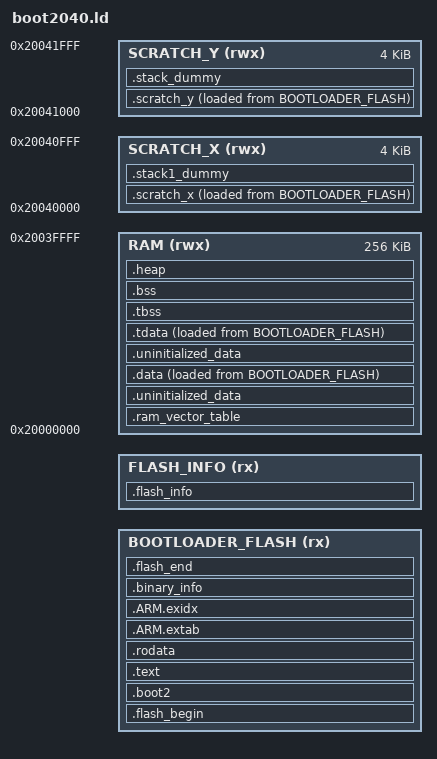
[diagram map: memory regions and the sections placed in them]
/* Based on pico-sdk/src/rp2_common/pico_crt0/rp2040/memmap_default.ld */

INCLUDE linker_definitions.ld

MEMORY
{
    BOOTLOADER_FLASH(rx) : ORIGIN = __FLASH_START, LENGTH = __BOOTLOADER_LENGTH
    FLASH_INFO(rx) : ORIGIN = __FLASH_INFO_START, LENGTH = __FLASH_INFO_LENGTH
    /*
    FLASH_APP(rx) : ORIGIN = __FLASH_APP_START, LENGTH = __FLASH_SLOT_LENGTH
    FLASH_DOWNLOAD_SLOT(rx) : ORIGIN = __FLASH_DOWNLOAD_SLOT_START, LENGTH = __FLASH_SLOT_LENGTH
    */
    RAM(rwx) : ORIGIN =  0x20000000, LENGTH = 256k
    SCRATCH_X(rwx) : ORIGIN = 0x20040000, LENGTH = 4k
    SCRATCH_Y(rwx) : ORIGIN = 0x20041000, LENGTH = 4k
}

ENTRY(_entry_point)

SECTIONS
{
    /* Second stage bootloader is prepended to the image. It must be 256 bytes big
       and checksummed. It is usually built by the boot_stage2 target
       in the Raspberry Pi Pico SDK
    */

    .flash_begin : {
        __flash_binary_start = .;
    } > BOOTLOADER_FLASH

    .boot2 : {
        __boot2_start__ = .;
        KEEP (*(.boot2))
        __boot2_end__ = .;
    } > BOOTLOADER_FLASH

    ASSERT(__boot2_end__ - __boot2_start__ == 256,
        "ERROR: Pico second stage bootloader must be 256 bytes in size")

    /* The second stage will always enter the image at the start of .text.
       The debugger will use the ELF entry point, which is the _entry_point
       symbol if present, otherwise defaults to start of .text.
       This can be used to transfer control back to the bootrom on debugger
       launches only, to perform proper flash setup.
    */

    .text : {
        __logical_binary_start = .;
        KEEP (*(.vectors))
        KEEP (*(.binary_info_header))
        __binary_info_header_end = .;
        KEEP (*(.reset))
        /* TODO revisit this now memset/memcpy/float in ROM */
        /* bit of a hack right now to exclude all floating point and time critical (e.g. memset, memcpy) code from
         * FLASH ... we will include any thing excluded here in .data below by default */
        *(.init)
        *(EXCLUDE_FILE(*libgcc.a: *libc.a:*lib_a-mem*.o *libm.a:) .text*)
        *(.fini)
        /* Pull all c'tors into .text */
        *crtbegin.o(.ctors)
        *crtbegin?.o(.ctors)
        *(EXCLUDE_FILE(*crtend?.o *crtend.o) .ctors)
        *(SORT(.ctors.*))
        *(.ctors)
        /* Followed by destructors */
        *crtbegin.o(.dtors)
        *crtbegin?.o(.dtors)
        *(EXCLUDE_FILE(*crtend?.o *crtend.o) .dtors)
        *(SORT(.dtors.*))
        *(.dtors)

        *(.eh_frame*)
        . = ALIGN(4);
    } > BOOTLOADER_FLASH

    .flash_info : {
        __flash_info_app_vtor = .;
        LONG(__FLASH_APP_START)
        __flash_info_download_slot_vtor = .;
        LONG(__FLASH_DOWNLOAD_SLOT_START)
        __flash_info_is_download_slot_valid = .;
        /* after flashing bootloader, download slot is invalid */
        LONG(0x00000000)
        __flash_info_is_firmware_is_swapped = .;
        /* after flashing bootloader, firmware has not yet been swapped */
        LONG(0x00000000)
        __flash_info_is_after_rollback = .;
        /* after flashing bootloader, app is not affter a rollback */
        LONG(0x00000000)
        __flash_info_should_rollback = .;
        /* after flashing bootloader, rollback shouldn't be performed */
        LONG(0x00000000)
    } > FLASH_INFO

    ASSERT(__flash_info_app_vtor == __FLASH_INFO_APP_HEADER,
            "__FLASH_INFO_APP_HEADER definition in linker_definitions.ld file is not valid")
    ASSERT(__flash_info_download_slot_vtor == __FLASH_INFO_DOWNLOAD_HEADER,
            "__FLASH_INFO_DOWNLOAD_HEADER definition in linker_definitions.ld file is not valid")
    ASSERT(__flash_info_is_download_slot_valid == __FLASH_INFO_IS_DOWNLOAD_SLOT_VALID,
            "__FLASH_INFO_IS_DOWNLOAD_SLOT_VALID definition in linker_definitions.ld file is not valid")
    ASSERT(__flash_info_is_firmware_is_swapped == __FLASH_INFO_IS_FIRMWARE_SWAPPED,
            "__FLASH_INFO_IS_FIRMWARE_SWAPPED definition in linker_definitions.ld file is not valid")
    ASSERT(__flash_info_is_after_rollback == __FLASH_INFO_IS_AFTER_ROLLBACK,
            "__FLASH_INFO_IS_AFTER_ROLLBACK definition in linker_definitions.ld file is not valid")
    ASSERT(__flash_info_should_rollback == __FLASH_INFO_SHOULD_ROLLBACK,
            "__FLASH_INFO_SHOULD_ROLLBACK definition in linker_definitions.ld file is not valid")

    .rodata : {
        *(EXCLUDE_FILE(*libgcc.a: *libc.a:*lib_a-mem*.o *libm.a:) .rodata*)
        . = ALIGN(4);
        *(SORT_BY_ALIGNMENT(SORT_BY_NAME(.flashdata*)))
        . = ALIGN(4);
    } > BOOTLOADER_FLASH

    .ARM.extab :
    {
        *(.ARM.extab* .gnu.linkonce.armextab.*)
    } > BOOTLOADER_FLASH

    __exidx_start = .;
    .ARM.exidx :
    {
        *(.ARM.exidx* .gnu.linkonce.armexidx.*)
    } > BOOTLOADER_FLASH
    __exidx_end = .;

    /* Machine inspectable binary information */
    . = ALIGN(4);
    __binary_info_start = .;
    .binary_info :
    {
        KEEP(*(.binary_info.keep.*))
        *(.binary_info.*)
    } > BOOTLOADER_FLASH
    __binary_info_end = .;
    . = ALIGN(4);

    __etext = .;

    .ram_vector_table (COPY): {
        *(.ram_vector_table)
    } > RAM

    .uninitialized_data (NOLOAD): {
        . = ALIGN(4);
        *(.uninitialized_data*)
    } > RAM

    .data : {
        __data_start__ = .;
        *(vtable)

        *(.time_critical*)

        /* remaining .text and .rodata; i.e. stuff we exclude above because we want it in RAM */
        *(.text*)
        . = ALIGN(4);
        *(.rodata*)
        . = ALIGN(4);

        *(.data*)

        . = ALIGN(4);
        *(.after_data.*)
        . = ALIGN(4);
        /* preinit data */
        PROVIDE_HIDDEN (__mutex_array_start = .);
        KEEP(*(SORT(.mutex_array.*)))
        KEEP(*(.mutex_array))
        PROVIDE_HIDDEN (__mutex_array_end = .);

        . = ALIGN(4);
        /* preinit data */
        PROVIDE_HIDDEN (__preinit_array_start = .);
        KEEP(*(SORT(.preinit_array.*)))
        KEEP(*(.preinit_array))
        PROVIDE_HIDDEN (__preinit_array_end = .);

        . = ALIGN(4);
        /* init data */
        PROVIDE_HIDDEN (__init_array_start = .);
        KEEP(*(SORT(.init_array.*)))
        KEEP(*(.init_array))
        PROVIDE_HIDDEN (__init_array_end = .);

        . = ALIGN(4);
        /* finit data */
        PROVIDE_HIDDEN (__fini_array_start = .);
        *(SORT(.fini_array.*))
        *(.fini_array)
        PROVIDE_HIDDEN (__fini_array_end = .);

        *(.jcr)
        . = ALIGN(4);
        __data_end__ = .;
    } > RAM AT> BOOTLOADER_FLASH

    .uninitialized_data (COPY): {
        . = ALIGN(4);
        *(.uninitialized_data*)
    } > RAM

    .tdata : {
        . = ALIGN(4);
		*(.tdata .tdata.* .gnu.linkonce.td.*)
        /* All data end */
        __tdata_end = .;
    } > RAM AT> BOOTLOADER_FLASH
    PROVIDE(__data_end__ = .);

    .tbss (NOLOAD) : {
        . = ALIGN(4);
        __bss_start__ = .;
        __tls_base = .;
        *(.tbss .tbss.* .gnu.linkonce.tb.*)
        *(.tcommon)

        __tls_end = .;
    } > RAM

    .bss (NOLOAD) : {
        . = ALIGN(4);
        __tbss_end = .;

        *(SORT_BY_ALIGNMENT(SORT_BY_NAME(.bss*)))
        *(COMMON)
        . = ALIGN(4);
        __bss_end__ = .;
    } > RAM

    .heap (NOLOAD):
    {
        __end__ = .;
        end = __end__;
        KEEP(*(.heap*))
    } > RAM
    /* historically on GCC sbrk was growing past __HeapLimit to __StackLimit, however
       to be more compatible, we now set __HeapLimit explicitly to where the end of the heap is */
    __HeapLimit = ORIGIN(RAM) + LENGTH(RAM);

    /* Start and end symbols must be word-aligned */
    .scratch_x : {
        __scratch_x_start__ = .;
        *(.scratch_x.*)
        . = ALIGN(4);
        __scratch_x_end__ = .;
    } > SCRATCH_X AT > BOOTLOADER_FLASH
    __scratch_x_source__ = LOADADDR(.scratch_x);

    .scratch_y : {
        __scratch_y_start__ = .;
        *(.scratch_y.*)
        . = ALIGN(4);
        __scratch_y_end__ = .;
    } > SCRATCH_Y AT > BOOTLOADER_FLASH
    __scratch_y_source__ = LOADADDR(.scratch_y);

    /* .stack*_dummy section doesn't contains any symbols. It is only
     * used for linker to calculate size of stack sections, and assign
     * values to stack symbols later
     *
     * stack1 section may be empty/missing if platform_launch_core1 is not used */

    /* by default we put core 0 stack at the end of scratch Y, so that if core 1
     * stack is not used then all of SCRATCH_X is free.
     */
    .stack1_dummy (NOLOAD):
    {
        *(.stack1*)
    } > SCRATCH_X
    .stack_dummy (NOLOAD):
    {
        KEEP(*(.stack*))
    } > SCRATCH_Y

    .flash_end : {
        PROVIDE(__flash_binary_end = .);
    } > BOOTLOADER_FLASH

    /* stack limit is poorly named, but historically is maximum heap ptr */
    __StackLimit = ORIGIN(RAM) + LENGTH(RAM);
    __StackOneTop = ORIGIN(SCRATCH_X) + LENGTH(SCRATCH_X);
    __StackTop = ORIGIN(SCRATCH_Y) + LENGTH(SCRATCH_Y);
    __StackOneBottom = __StackOneTop - SIZEOF(.stack1_dummy);
    __StackBottom = __StackTop - SIZEOF(.stack_dummy);
    PROVIDE(__stack = __StackTop);

    /* picolibc and LLVM */
    PROVIDE (__heap_start = __end__);
    PROVIDE (__heap_end = __HeapLimit);
    PROVIDE( __tls_align = MAX(ALIGNOF(.tdata), ALIGNOF(.tbss)) );
    PROVIDE( __tls_size_align = (__tls_size + __tls_align - 1) & ~(__tls_align - 1));
    PROVIDE( __arm32_tls_tcb_offset = MAX(8, __tls_align) );

    /* llvm-libc */
    PROVIDE (_end = __end__);
    PROVIDE (__llvm_libc_heap_limit = __HeapLimit);

    /* Check if data + heap + stack exceeds RAM limit */
    ASSERT(__StackLimit >= __HeapLimit, "region RAM overflowed")

    ASSERT( __binary_info_header_end - __logical_binary_start <= 256, "Binary info must be in first 256 bytes of the binary")
    /* todo assert on extra code */
}

